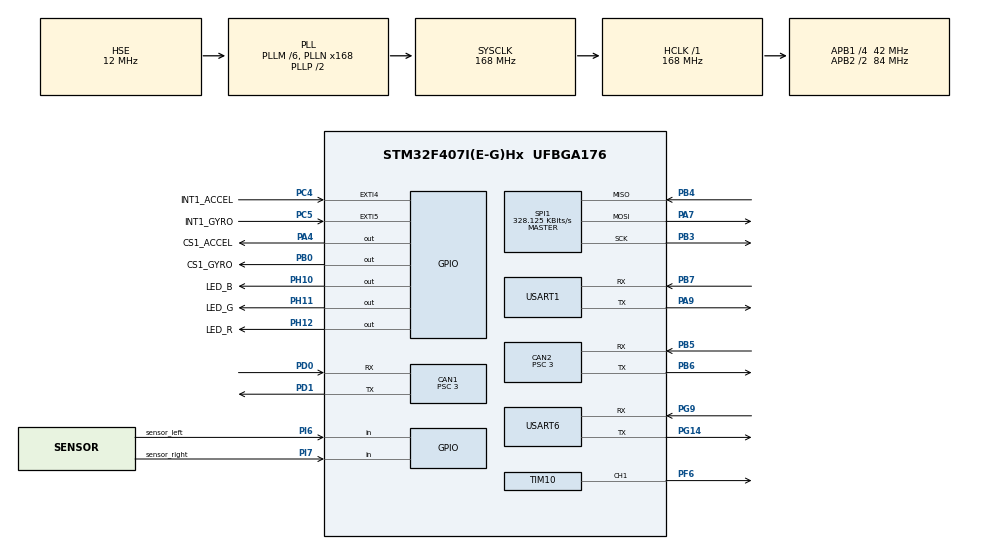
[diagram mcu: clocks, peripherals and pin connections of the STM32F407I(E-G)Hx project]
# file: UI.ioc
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CAN1.ABOM=ENABLE
CAN1.BS1=CAN_BS1_10TQ
CAN1.BS2=CAN_BS2_3TQ
CAN1.CalculateBaudRate=1000000
CAN1.CalculateTimeBit=999.99
CAN1.CalculateTimeQuantum=71.42857142857143
CAN1.Prescaler=3
CAN2.ABOM=ENABLE
CAN2.BS1=CAN_BS1_10TQ
CAN2.BS2=CAN_BS2_3TQ
CAN2.CalculateBaudRate=1000000
CAN2.CalculateTimeBit=999.99
CAN2.CalculateTimeQuantum=71.42857142857143
CAN2.Prescaler=3
CAN2.SJW=CAN_SJW_4TQ
Dma.Request0=USART6_RX
Dma.Request1=SPI1_RX
Dma.Request2=SPI1_TX
Dma.SPI1_RX.1.Direction=DMA_PERIPH_TO_MEMORY
Dma.SPI1_RX.1.FIFOMode=DMA_FIFOMODE_DISABLE
Dma.SPI1_RX.1.Instance=DMA2_Stream2
Dma.SPI1_RX.1.MemDataAlignment=DMA_MDATAALIGN_BYTE
Dma.SPI1_RX.1.MemInc=DMA_MINC_ENABLE
Dma.SPI1_RX.1.Mode=DMA_NORMAL
Dma.SPI1_RX.1.PeriphDataAlignment=DMA_PDATAALIGN_BYTE
Dma.SPI1_RX.1.PeriphInc=DMA_PINC_DISABLE
Dma.SPI1_RX.1.Priority=DMA_PRIORITY_VERY_HIGH
Dma.SPI1_TX.2.Direction=DMA_MEMORY_TO_PERIPH
Dma.SPI1_TX.2.FIFOMode=DMA_FIFOMODE_DISABLE
Dma.SPI1_TX.2.Instance=DMA2_Stream3
Dma.SPI1_TX.2.MemDataAlignment=DMA_MDATAALIGN_BYTE
Dma.SPI1_TX.2.MemInc=DMA_MINC_ENABLE
Dma.SPI1_TX.2.Mode=DMA_NORMAL
Dma.SPI1_TX.2.PeriphDataAlignment=DMA_PDATAALIGN_BYTE
Dma.SPI1_TX.2.PeriphInc=DMA_PINC_DISABLE
Dma.SPI1_TX.2.Priority=DMA_PRIORITY_HIGH
Dma.USART6_RX.0.Direction=DMA_PERIPH_TO_MEMORY
Dma.USART6_RX.0.FIFOMode=DMA_FIFOMODE_DISABLE
Dma.USART6_RX.0.Instance=DMA2_Stream1
Dma.USART6_RX.0.MemDataAlignment=DMA_MDATAALIGN_BYTE
Dma.USART6_RX.0.MemInc=DMA_MINC_ENABLE
Dma.USART6_RX.0.Mode=DMA_NORMAL
Dma.USART6_RX.0.PeriphDataAlignment=DMA_PDATAALIGN_BYTE
Dma.USART6_RX.0.PeriphInc=DMA_PINC_DISABLE
Dma.USART6_RX.0.Priority=DMA_PRIORITY_VERY_HIGH
FREERTOS.INCLUDE_uxTaskGetStackHighWaterMark=1
FREERTOS.INCLUDE_vTaskDelayUntil=1
FREERTOS.Tasks01=defaultTask,-3,128,StartDefaultTask,As weak,NULL,Dynamic,NULL,NULL;myTask02,-1,256,StartTask02,As weak,NULL,Dynamic,NULL,NULL;myTask03,-2,256,StartTask03,As weak,NULL,Dynamic,NULL,NULL;myTask04,-2,256,StartTask04,As weak,NULL,Dynamic,NULL,NULL;myTask05,-2,256,StartTask05,As weak,NULL,Dynamic,NULL,NULL
FREERTOS.configCHECK_FOR_STACK_OVERFLOW=1
FREERTOS.configTIMER_TASK_STACK_DEPTH=128
FREERTOS.configTOTAL_HEAP_SIZE=8000
FREERTOS.configUSE_TIMERS=1
FREERTOS.configUSE_TRACE_FACILITY=1
Mcu.Family=STM32F4
Mcu.Name=STM32F407I(E-G)Hx
Mcu.Package=UFBGA176
NVIC.CAN1_RX0_IRQn=true\:7\:0\:true\:false\:true\:false\:true\:true
NVIC.CAN1_TX_IRQn=true\:7\:0\:true\:false\:true\:false\:true\:true
NVIC.CAN2_RX0_IRQn=true\:7\:0\:true\:false\:true\:true\:true\:true
NVIC.CAN2_TX_IRQn=true\:7\:0\:true\:false\:true\:false\:true\:true
NVIC.DMA2_Stream1_IRQn=true\:5\:0\:false\:false\:true\:false\:false\:true
NVIC.DMA2_Stream2_IRQn=true\:5\:0\:true\:false\:true\:false\:false\:true
NVIC.DMA2_Stream3_IRQn=true\:5\:0\:false\:false\:true\:true\:false\:true
NVIC.EXTI4_IRQn=true\:5\:0\:false\:false\:true\:true\:true\:true
NVIC.EXTI9_5_IRQn=true\:5\:0\:false\:false\:true\:true\:true\:true
NVIC.PriorityGroup=NVIC_PRIORITYGROUP_4
NVIC.TIM1_UP_TIM10_IRQn=true\:5\:0\:false\:false\:true\:false\:true\:true
NVIC.USART1_IRQn=true\:7\:0\:true\:false\:true\:true\:true\:true
NVIC.USART6_IRQn=true\:4\:0\:true\:false\:true\:false\:true\:true
PA13.Mode=Serial_Wire
PA13.Signal=SYS_JTMS-SWDIO
PA14.Mode=Serial_Wire
PA14.Signal=SYS_JTCK-SWCLK
PA4.GPIO_Label=CS1_ACCEL
PA4.GPIO_PuPd=GPIO_PULLUP
PA4.GPIO_Speed=GPIO_SPEED_FREQ_HIGH
PA4.PinState=GPIO_PIN_SET
PA4.Signal=GPIO_Output
PA7.Mode=Full_Duplex_Master
PA7.Signal=SPI1_MOSI
PA9.GPIO_Mode=GPIO_MODE_AF_PP
PA9.Mode=Asynchronous
PA9.Signal=USART1_TX
PB0.GPIO_Label=CS1_GYRO
PB0.GPIO_PuPd=GPIO_PULLUP
PB0.GPIO_Speed=GPIO_SPEED_FREQ_HIGH
PB0.PinState=GPIO_PIN_SET
PB0.Signal=GPIO_Output
PB3.Mode=Full_Duplex_Master
PB3.Signal=SPI1_SCK
PB4.Mode=Full_Duplex_Master
PB4.Signal=SPI1_MISO
PB5.Mode=CAN_Activate
PB5.Signal=CAN2_RX
PB6.Mode=CAN_Activate
PB6.Signal=CAN2_TX
PB7.Mode=Asynchronous
PB7.Signal=USART1_RX
PC4.GPIO_Label=INT1_ACCEL
PC4.GPIO_ModeDefaultEXTI=GPIO_MODE_IT_FALLING
PC4.GPIO_PuPd=GPIO_PULLUP
PC4.Signal=GPXTI4
PC5.GPIO_Label=INT1_GYRO
PC5.GPIO_ModeDefaultEXTI=GPIO_MODE_IT_FALLING
PC5.GPIO_PuPd=GPIO_PULLUP
PC5.Signal=GPXTI5
PD0.Mode=CAN_Activate
PD0.Signal=CAN1_RX
PD1.Mode=CAN_Activate
PD1.Signal=CAN1_TX
PD5.Signal=USART2_TX
PD6.Signal=USART2_RX
PF6.GPIO_PuPd=GPIO_PULLUP
PF6.GPIO_Speed=GPIO_SPEED_FREQ_HIGH
PF6.Signal=S_TIM10_CH1
PG14.Mode=Asynchronous
PG14.Signal=USART6_TX
PG9.GPIO_Mode=GPIO_MODE_AF_PP
PG9.Mode=Asynchronous
PG9.Signal=USART6_RX
PH0-OSC_IN.Mode=HSE-External-Oscillator
PH0-OSC_IN.Signal=RCC_OSC_IN
PH1-OSC_OUT.Mode=HSE-External-Oscillator
PH1-OSC_OUT.Signal=RCC_OSC_OUT
PH10.GPIO_Label=LED_B
PH10.GPIO_PuPd=GPIO_PULLUP
PH10.GPIO_Speed=GPIO_SPEED_FREQ_HIGH
PH10.PinState=GPIO_PIN_SET
PH10.Signal=GPIO_Output
PH11.GPIO_Label=LED_G
PH11.GPIO_PuPd=GPIO_PULLUP
PH11.GPIO_Speed=GPIO_SPEED_FREQ_HIGH
PH11.PinState=GPIO_PIN_SET
PH11.Signal=GPIO_Output
PH12.GPIO_Label=LED_R
PH12.GPIO_PuPd=GPIO_PULLUP
PH12.GPIO_Speed=GPIO_SPEED_FREQ_HIGH
PH12.PinState=GPIO_PIN_SET
PH12.Signal=GPIO_Output
PI6.GPIO_Label=sensor_left
PI6.GPIO_PuPd=GPIO_PULLUP
PI6.Signal=GPIO_Input
PI7.GPIO_Label=sensor_right
PI7.GPIO_PuPd=GPIO_PULLUP
PI7.Signal=GPIO_Input
ProjectManager.HeapSize=0x200
ProjectManager.StackSize=0x400
ProjectManager.TargetToolchain=MDK-ARM V5
RCC.48MHZClocksFreq_Value=84000000
RCC.AHBFreq_Value=168000000
RCC.APB1CLKDivider=RCC_HCLK_DIV4
RCC.APB1Freq_Value=42000000
RCC.APB1TimFreq_Value=84000000
RCC.APB2CLKDivider=RCC_HCLK_DIV2
RCC.APB2Freq_Value=84000000
RCC.APB2TimFreq_Value=168000000
RCC.CortexFreq_Value=168000000
RCC.HCLKFreq_Value=168000000
RCC.HSE_VALUE=12000000
RCC.HSI_VALUE=16000000
RCC.LSE_VALUE=32768
RCC.PLLM=6
RCC.PLLN=168
RCC.PLLSourceVirtual=RCC_PLLSOURCE_HSE
RCC.SYSCLKFreq_VALUE=168000000
RCC.SYSCLKSource=RCC_SYSCLKSOURCE_PLLCLK
RCC.VCOOutputFreq_Value=336000000
SH.S_TIM10_CH1.0=TIM10_CH1,PWM Generation1 CH1
SPI1.BaudRatePrescaler=SPI_BAUDRATEPRESCALER_256
SPI1.CLKPhase=SPI_PHASE_2EDGE
SPI1.CLKPolarity=SPI_POLARITY_HIGH
SPI1.CalculateBaudRate=328.125 KBits/s
SPI1.Direction=SPI_DIRECTION_2LINES
SPI1.Mode=SPI_MODE_MASTER
SPI1.VirtualType=VM_MASTER
TIM10.Channel=TIM_CHANNEL_1
TIM10.Period=4999
USART1.VirtualMode=VM_ASYNC
USART6.VirtualMode=VM_ASYNC
VP_FREERTOS_VS_CMSIS_V1.Mode=CMSIS_V1
VP_TIM10_VS_ClockSourceINT.Mode=Enable_Timer
board=custom

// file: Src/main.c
/* USER CODE BEGIN Header */
/**
  ******************************************************************************
  * @file           : main.c
  * @brief          : Main program body
  ******************************************************************************
  * @attention
  *
  * <h2><center>&copy; Copyright (c) 2021 STMicroelectronics.
  * All rights reserved.</center></h2>
  *
  * This software component is licensed by ST under BSD 3-Clause license,
  * the "License"; You may not use this file except in compliance with the
  * License. You may obtain a copy of the License at:
  *                        opensource.org/licenses/BSD-3-Clause
  *
  ******************************************************************************
  */
/* USER CODE END Header */
#include "main.h"
#include "cmsis_os.h"
#include "can.h"
#include "dma.h"
#include "spi.h"
#include "tim.h"
#include "usart.h"
#include "gpio.h"

/* USER CODE BEGIN Includes */
#include "bsp_usart.h"
#include "stdio.h"
#include "bsp_can.h"
#include "BMI088driver.h"

/* USER CODE END Includes */

void SystemClock_Config(void);
void MX_FREERTOS_Init(void);

int main(void)
{

  /* MCU Configuration--------------------------------------------------------*/

  /* Reset of all peripherals, Initializes the Flash interface and the Systick. */
  HAL_Init();

  /* Configure the system clock */
  SystemClock_Config();

  /* Initialize all configured peripherals */
  MX_GPIO_Init();
  MX_DMA_Init();
  MX_USART1_UART_Init();
  MX_USART6_UART_Init();
  MX_CAN1_Init();
  MX_CAN2_Init();
  MX_SPI1_Init();
  MX_TIM10_Init();
  /* USER CODE BEGIN 2 */
  MY_USART_Init();
  MY_CAN_Init();
  while(BMI088_init())
  {
      ;
  }
  /* USER CODE END 2 */

  /* Call init function for freertos objects (in freertos.c) */
  MX_FREERTOS_Init();
  /* Start scheduler */
  osKernelStart();

  /* We should never get here as control is now taken by the scheduler */
  /* Infinite loop */
  while (1)
  {

  }
}

void SystemClock_Config(void)
{
  RCC_OscInitTypeDef RCC_OscInitStruct = {0};
  RCC_ClkInitTypeDef RCC_ClkInitStruct = {0};

  /** Configure the main internal regulator output voltage
  */
  __HAL_RCC_PWR_CLK_ENABLE();
  __HAL_PWR_VOLTAGESCALING_CONFIG(PWR_REGULATOR_VOLTAGE_SCALE1);
  /** Initializes the RCC Oscillators according to the specified parameters
  * in the RCC_OscInitTypeDef structure.
  */
  RCC_OscInitStruct.OscillatorType = RCC_OSCILLATORTYPE_HSE;
  RCC_OscInitStruct.HSEState = RCC_HSE_ON;
  RCC_OscInitStruct.PLL.PLLState = RCC_PLL_ON;
  RCC_OscInitStruct.PLL.PLLSource = RCC_PLLSOURCE_HSE;
  RCC_OscInitStruct.PLL.PLLM = 6;
  RCC_OscInitStruct.PLL.PLLN = 168;
  RCC_OscInitStruct.PLL.PLLP = RCC_PLLP_DIV2;
  RCC_OscInitStruct.PLL.PLLQ = 4;
  if (HAL_RCC_OscConfig(&RCC_OscInitStruct) != HAL_OK)
  {
    Error_Handler();
  }
  /** Initializes the CPU, AHB and APB buses clocks
  */
  RCC_ClkInitStruct.ClockType = RCC_CLOCKTYPE_HCLK|RCC_CLOCKTYPE_SYSCLK
                              |RCC_CLOCKTYPE_PCLK1|RCC_CLOCKTYPE_PCLK2;
  RCC_ClkInitStruct.SYSCLKSource = RCC_SYSCLKSOURCE_PLLCLK;
  RCC_ClkInitStruct.AHBCLKDivider = RCC_SYSCLK_DIV1;
  RCC_ClkInitStruct.APB1CLKDivider = RCC_HCLK_DIV4;
  RCC_ClkInitStruct.APB2CLKDivider = RCC_HCLK_DIV2;

  if (HAL_RCC_ClockConfig(&RCC_ClkInitStruct, FLASH_LATENCY_5) != HAL_OK)
  {
    Error_Handler();
  }
}

void Error_Handler(void)
{
}

/************************ (C) COPYRIGHT STMicroelectronics *****END OF FILE****/

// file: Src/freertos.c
/* USER CODE BEGIN Header */
/**
  ******************************************************************************
  * File Name          : freertos.c
  * Description        : Code for freertos applications
  ******************************************************************************
  * @attention
  *
  * <h2><center>&copy; Copyright (c) 2021 STMicroelectronics.
  * All rights reserved.</center></h2>
  *
  * This software component is licensed by ST under Ultimate Liberty license
  * SLA0044, the "License"; You may not use this file except in compliance with
  * the License. You may obtain a copy of the License at:
  *                             www.st.com/SLA0044
  *
  ******************************************************************************
  */
/* USER CODE END Header */

#include "FreeRTOS.h"
#include "task.h"
#include "main.h"
#include "cmsis_os.h"

osThreadId defaultTaskHandle;
osThreadId myTask02Handle;
osThreadId myTask03Handle;
osThreadId myTask04Handle;
osThreadId myTask05Handle;

void StartDefaultTask(void const * argument);
void StartTask02(void const * argument);
void StartTask03(void const * argument);
void StartTask04(void const * argument);
void StartTask05(void const * argument);

void MX_FREERTOS_Init(void); /* (MISRA C 2004 rule 8.1) */

/* GetIdleTaskMemory prototype (linked to static allocation support) */
void vApplicationGetIdleTaskMemory( StaticTask_t **ppxIdleTaskTCBBuffer, StackType_t **ppxIdleTaskStackBuffer, uint32_t *pulIdleTaskStackSize );

/* GetTimerTaskMemory prototype (linked to static allocation support) */
void vApplicationGetTimerTaskMemory( StaticTask_t **ppxTimerTaskTCBBuffer, StackType_t **ppxTimerTaskStackBuffer, uint32_t *pulTimerTaskStackSize );

/* Hook prototypes */
void vApplicationStackOverflowHook(xTaskHandle xTask, signed char *pcTaskName);

/* USER CODE BEGIN 4 */
__weak void vApplicationStackOverflowHook(xTaskHandle xTask, signed char *pcTaskName)
{
   /* Run time stack overflow checking is performed if
   configCHECK_FOR_STACK_OVERFLOW is defined to 1 or 2. This hook function is
   called if a stack overflow is detected. */
}
/* USER CODE END 4 */

/* USER CODE BEGIN GET_IDLE_TASK_MEMORY */
static StaticTask_t xIdleTaskTCBBuffer;
static StackType_t xIdleStack[configMINIMAL_STACK_SIZE];

void vApplicationGetIdleTaskMemory( StaticTask_t **ppxIdleTaskTCBBuffer, StackType_t **ppxIdleTaskStackBuffer, uint32_t *pulIdleTaskStackSize )
{
  *ppxIdleTaskTCBBuffer = &xIdleTaskTCBBuffer;
  *ppxIdleTaskStackBuffer = &xIdleStack[0];
  *pulIdleTaskStackSize = configMINIMAL_STACK_SIZE;
  /* place for user code */
}
/* USER CODE END GET_IDLE_TASK_MEMORY */

/* USER CODE BEGIN GET_TIMER_TASK_MEMORY */
static StaticTask_t xTimerTaskTCBBuffer;
static StackType_t xTimerStack[configTIMER_TASK_STACK_DEPTH];

void vApplicationGetTimerTaskMemory( StaticTask_t **ppxTimerTaskTCBBuffer, StackType_t **ppxTimerTaskStackBuffer, uint32_t *pulTimerTaskStackSize )
{
  *ppxTimerTaskTCBBuffer = &xTimerTaskTCBBuffer;
  *ppxTimerTaskStackBuffer = &xTimerStack[0];
  *pulTimerTaskStackSize = configTIMER_TASK_STACK_DEPTH;
  /* place for user code */
}
/* USER CODE END GET_TIMER_TASK_MEMORY */

void MX_FREERTOS_Init(void) {

  /* Create the thread(s) */
  /* definition and creation of defaultTask */
  osThreadDef(defaultTask, StartDefaultTask, osPriorityIdle, 0, 128);
  defaultTaskHandle = osThreadCreate(osThread(defaultTask), NULL);

  /* definition and creation of myTask02 */
  osThreadDef(myTask02, StartTask02, osPriorityBelowNormal, 0, 256);
  myTask02Handle = osThreadCreate(osThread(myTask02), NULL);

  /* definition and creation of myTask03 */
  osThreadDef(myTask03, StartTask03, osPriorityLow, 0, 256);
  myTask03Handle = osThreadCreate(osThread(myTask03), NULL);

  /* definition and creation of myTask04 */
  osThreadDef(myTask04, StartTask04, osPriorityLow, 0, 256);
  myTask04Handle = osThreadCreate(osThread(myTask04), NULL);

  /* definition and creation of myTask05 */
//  osThreadDef(myTask05, StartTask05, osPriorityLow, 0, 256);
//  myTask05Handle = osThreadCreate(osThread(myTask05), NULL);

}

__weak void StartDefaultTask(void const * argument)
{
  for(;;)
  {
    osDelay(1);
  }
}

__weak void StartTask02(void const * argument)
{
  for(;;)
  {
    osDelay(1);
  }
}

__weak void StartTask03(void const * argument)
{
  for(;;)
  {
    osDelay(1);
  }
}

__weak void StartTask04(void const * argument)
{
  for(;;)
  {
    osDelay(1);
  }
}

__weak void StartTask05(void const * argument)
{
  for(;;)
  {
    osDelay(1);
  }
}

/************************ (C) COPYRIGHT STMicroelectronics *****END OF FILE****/
